VERSION ""

NS_ :

BS_:

BU_: Kistler_S350

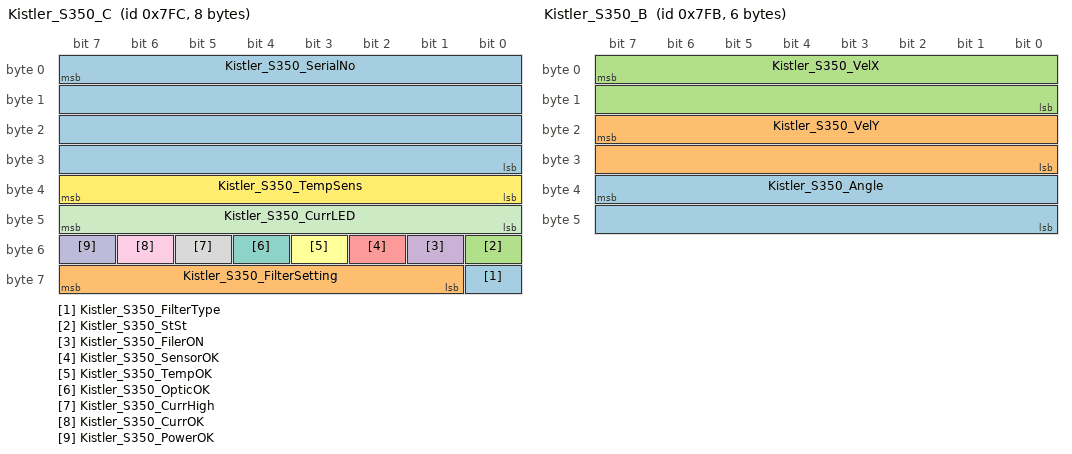
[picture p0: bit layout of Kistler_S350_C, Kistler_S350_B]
BO_ 2044 Kistler_S350_C: 8 Kistler_S350
 SG_ Kistler_S350_FilterType : 56|1@0+ (1,0) [0|1] "" Vector__XXX
 SG_ Kistler_S350_FilterSetting : 63|7@0+ (1,0) [0|127] "" Vector__XXX
 SG_ Kistler_S350_StSt : 48|1@0+ (1,0) [0|1] "" Vector__XXX
 SG_ Kistler_S350_FilerON : 49|1@0+ (1,0) [0|1] "" Vector__XXX
 SG_ Kistler_S350_SensorOK : 50|1@0+ (1,0) [0|1] "" Vector__XXX
 SG_ Kistler_S350_TempOK : 51|1@0+ (1,0) [0|1] "" Vector__XXX
 SG_ Kistler_S350_OpticOK : 52|1@0+ (1,0) [0|1] "" Vector__XXX
 SG_ Kistler_S350_CurrHigh : 53|1@0+ (1,0) [0|1] "" Vector__XXX
 SG_ Kistler_S350_CurrOK : 54|1@0+ (1,0) [0|1] "" Vector__XXX
 SG_ Kistler_S350_PowerOK : 55|1@0+ (1,0) [0|1] "" Vector__XXX
 SG_ Kistler_S350_CurrLED : 47|8@0+ (0.01,0) [0|2.55] "A" Vector__XXX
 SG_ Kistler_S350_TempSens : 39|8@0- (1,0) [-128|127] "°C" Vector__XXX
 SG_ Kistler_S350_SerialNo : 7|32@0+ (1,0) [0|4294970000] "" Vector__XXX

BO_ 2043 Kistler_S350_B: 6 Kistler_S350
 SG_ Kistler_S350_Angle : 39|16@0- (0.01,0) [-45|45] "°" Vector__XXX
 SG_ Kistler_S350_VelY : 23|16@0- (0.036,0) [-100|100] "km/h" Vector__XXX
 SG_ Kistler_S350_VelX : 7|16@0+ (0.036,0) [0|400] "km/h" Vector__XXX

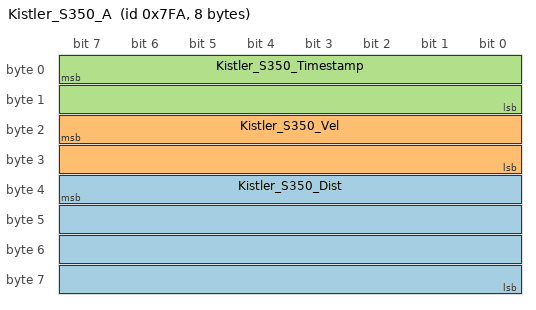
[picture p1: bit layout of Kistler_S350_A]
BO_ 2042 Kistler_S350_A: 8 Kistler_S350
 SG_ Kistler_S350_Dist : 39|32@0+ (0.001,0) [0|4294970] "m" Vector__XXX
 SG_ Kistler_S350_Vel : 23|16@0+ (0.036,0) [0|400] "km/h" Vector__XXX
 SG_ Kistler_S350_Timestamp : 7|16@0+ (1,0) [0|65535] "" Vector__XXX

CM_ BO_ 2044 "Device status";
CM_ BO_ 2043 "Velocity X, Velocity Y, Slip angle";
CM_ BO_ 2042 "Timestamp, velocity, distance";
BA_DEF_  "BusType" STRING ;
BA_DEF_DEF_  "BusType" "";
BA_ "BusType" "CAN";
